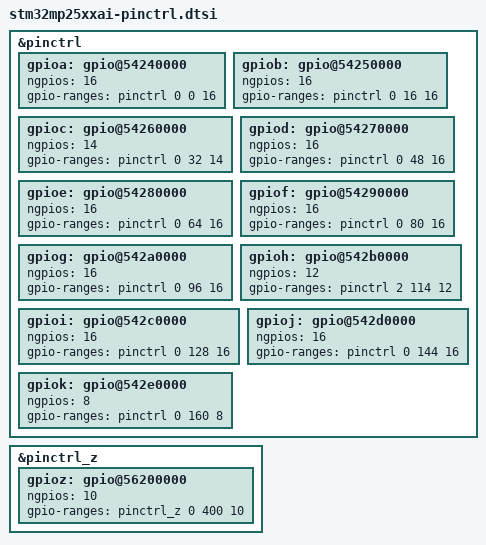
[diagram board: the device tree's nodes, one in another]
/*
 * Copyright (c) 2026, STMicroelectronics - All Rights Reserved
 *
 * SPDX-License-Identifier: Apache-2.0
 */

&pinctrl {
        #gpio-range-cells = <3>;
	
	gpioa: gpio@54240000 {
		status = "okay";
		ngpios = <16>;
		gpio-ranges = <&pinctrl 0 0 16>;
	};

	gpiob: gpio@54250000 {
		status = "okay";
		ngpios = <16>;
		gpio-ranges = <&pinctrl 0 16 16>;
	};

	gpioc: gpio@54260000 {
		status = "okay";
		ngpios = <14>;
		gpio-ranges = <&pinctrl 0 32 14>;
	};

	gpiod: gpio@54270000 {
		status = "okay";
		ngpios = <16>;
		gpio-ranges = <&pinctrl 0 48 16>;
	};

	gpioe: gpio@54280000 {
		status = "okay";
		ngpios = <16>;
		gpio-ranges = <&pinctrl 0 64 16>;
	};

	gpiof: gpio@54290000 {
		status = "okay";
		ngpios = <16>;
		gpio-ranges = <&pinctrl 0 80 16>;
	};

	gpiog: gpio@542a0000 {
		status = "okay";
		ngpios = <16>;
		gpio-ranges = <&pinctrl 0 96 16>;
	};

	gpioh: gpio@542b0000 {
		status = "okay";
		ngpios = <12>;
		gpio-ranges = <&pinctrl 2 114 12>;
	};

	gpioi: gpio@542c0000 {
		status = "okay";
		ngpios = <16>;
		gpio-ranges = <&pinctrl 0 128 16>;
	};

	gpioj: gpio@542d0000 {
		status = "okay";
		ngpios = <16>;
		gpio-ranges = <&pinctrl 0 144 16>;
	};

	gpiok: gpio@542e0000 {
		status = "okay";
		ngpios = <8>;
		gpio-ranges = <&pinctrl 0 160 8>;
	};
};

&pinctrl_z {
	gpioz: gpio@56200000 {
		status = "okay";
		ngpios = <10>;
		gpio-ranges = <&pinctrl_z 0 400 10>;
	};
};
